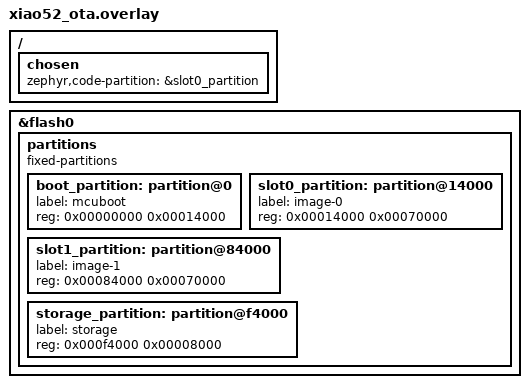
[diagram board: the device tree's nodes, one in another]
/*
 * MCUboot flash layout for omi-xiao52 (nRF52840, 1 MB flash) — applied to the
 * APPLICATION image. Replaces the stock UF2/SoftDevice partition table with a
 * MCUboot boot + dual-slot layout so firmware can be updated OTA over BLE
 * (mcumgr SMP). The matching layout for the MCUboot image itself lives in
 * sysbuild/mcuboot.overlay (identical partitions, different code-partition).
 *
 *   0x00000000  mcuboot        64 kB
 *   0x00010000  slot0 (app)   448 kB
 *   0x00080000  slot1 (dfu)   448 kB
 *   0x000f0000  storage        32 kB
 */

/ {
	chosen {
		zephyr,code-partition = &slot0_partition;
	};
};

&flash0 {
	/delete-node/ partitions;

	partitions {
		compatible = "fixed-partitions";
		#address-cells = <1>;
		#size-cells = <1>;

		boot_partition: partition@0 {
			label = "mcuboot";
			reg = <0x00000000 0x00014000>;
		};

		slot0_partition: partition@14000 {
			label = "image-0";
			reg = <0x00014000 0x00070000>;
		};

		slot1_partition: partition@84000 {
			label = "image-1";
			reg = <0x00084000 0x00070000>;
		};

		storage_partition: partition@f4000 {
			label = "storage";
			reg = <0x000f4000 0x00008000>;
		};
	};
};
